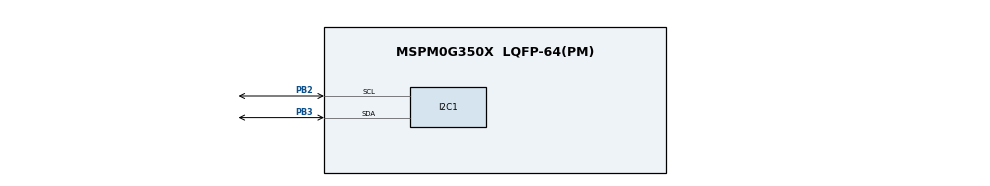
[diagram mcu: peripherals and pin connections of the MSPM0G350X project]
/**
 * @cliArgs --device "MSPM0G350X" --part "Default" --package "LQFP-64(PM)" --product "mspm0_sdk@2.03.00.08"
 * @versions {"tool":"1.21.0+3721"}
 */

/**
 * Import the modules used in this configuration.
 */
const GPIO  = scripting.addModule("/ti/driverlib/GPIO", {}, false);
const GPIO1 = GPIO.addInstance();
const I2C   = scripting.addModule("/ti/driverlib/I2C", {}, false);
const I2C1  = I2C.addInstance();

/**
 * Write custom configuration values to the imported modules.
 */
GPIO1.$name                          = "GPIO_LEDS";
GPIO1.port                           = "PORTA";
GPIO1.associatedPins.create(2);
GPIO1.associatedPins[0].$name        = "USER_LED_1";
GPIO1.associatedPins[0].assignedPin  = "0";
GPIO1.associatedPins[1].$name        = "USER_TEST";
GPIO1.associatedPins[1].initialValue = "SET";
GPIO1.associatedPins[1].assignedPin  = "15";

const Board = scripting.addModule("/ti/driverlib/Board", {}, false);

I2C1.basicEnableController             = true;
I2C1.$name                             = "I2C";
I2C1.advAnalogGlitchFilter             = "DISABLED";
I2C1.basicControllerBusSpeed           = 400000;
I2C1.peripheral.sdaPin.$assign         = "PB3";
I2C1.peripheral.sclPin.$assign         = "PB2";
I2C1.sdaPinConfig.$name                = "ti_driverlib_gpio_GPIOPinGeneric0";
I2C1.sdaPinConfig.hideOutputInversion  = scripting.forceWrite(false);
I2C1.sdaPinConfig.onlyInternalResistor = scripting.forceWrite(false);
I2C1.sdaPinConfig.passedPeripheralType = scripting.forceWrite("Digital");
I2C1.sclPinConfig.$name                = "ti_driverlib_gpio_GPIOPinGeneric1";
I2C1.sclPinConfig.hideOutputInversion  = scripting.forceWrite(false);
I2C1.sclPinConfig.onlyInternalResistor = scripting.forceWrite(false);
I2C1.sclPinConfig.passedPeripheralType = scripting.forceWrite("Digital");

const SYSCTL                 = scripting.addModule("/ti/driverlib/SYSCTL", {}, false);
SYSCTL.forceDefaultClkConfig = true;
SYSCTL.clockTreeEn           = true;

/**
 * Pinmux solution for unlocked pins/peripherals. This ensures that minor changes to the automatic solver in a future
 * version of the tool will not impact the pinmux you originally saw.  These lines can be completely deleted in order to
 * re-solve from scratch.
 */
GPIO1.associatedPins[0].pin.$suggestSolution = "PA0";
GPIO1.associatedPins[1].pin.$suggestSolution = "PA15";
Board.peripheral.$suggestSolution            = "DEBUGSS";
Board.peripheral.swclkPin.$suggestSolution   = "PA20";
Board.peripheral.swdioPin.$suggestSolution   = "PA19";
I2C1.peripheral.$suggestSolution             = "I2C1";
